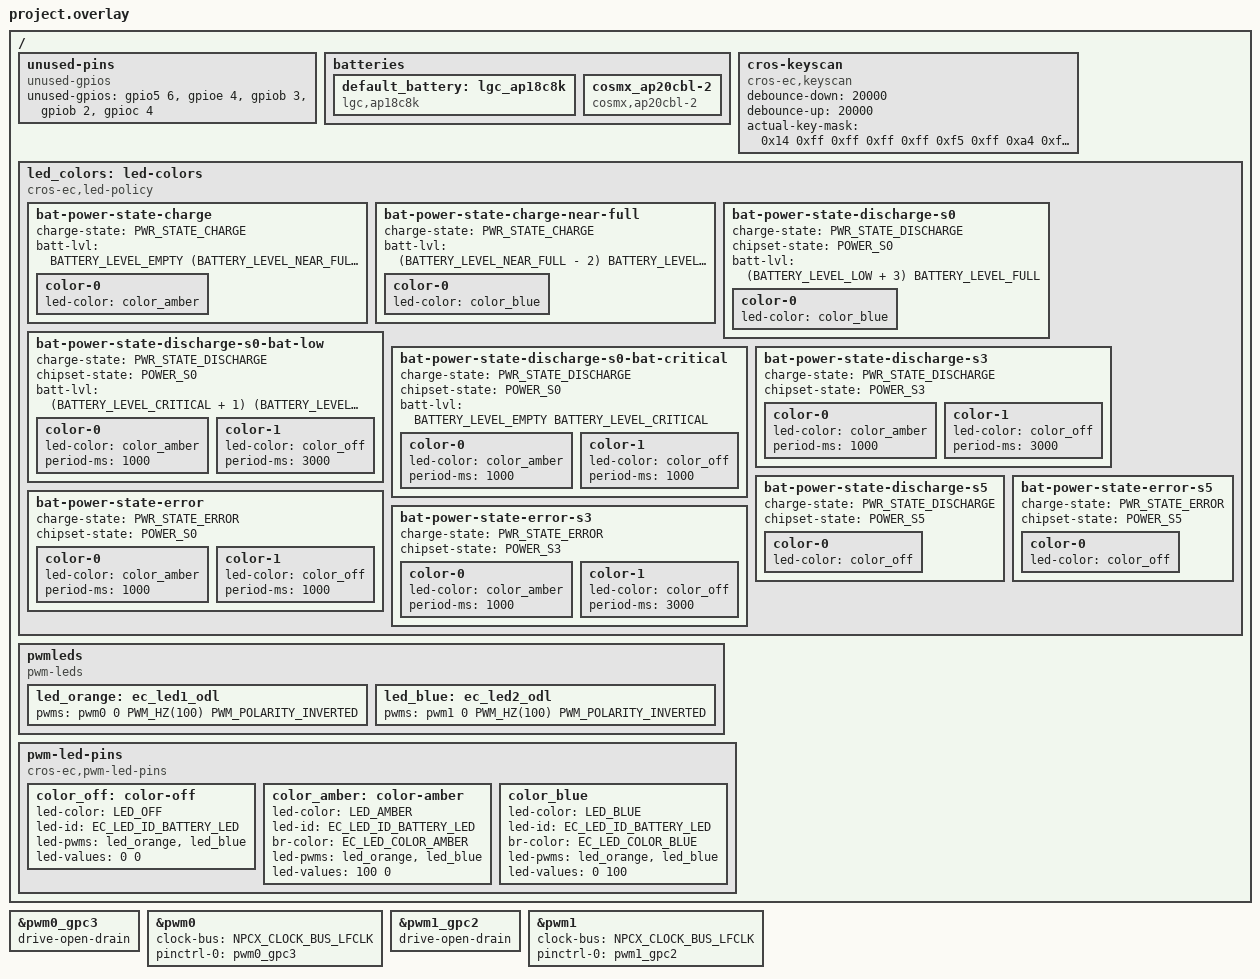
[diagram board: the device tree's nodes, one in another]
/* Copyright 2022 The ChromiumOS Authors
 * Use of this source code is governed by a BSD-style license that can be
 * found in the LICENSE file.
 */

/* Corsola program common DTS includes */

#include "../common.dtsi"
#include "../power_signal.dtsi"
#include "../usba.dtsi"
#include "../npcx_adc.dtsi"
#include "../npcx_gpio.dtsi"
#include "../npcx_host_interface.dtsi"
#include "../npcx_i2c.dtsi"
#include "../npcx_interrupts.dtsi"
#include "../npcx_keyboard.dtsi"
#include "../npcx_usbc.dtsi"
#include "../npcx_default_gpio_pinctrl.dtsi"
#include <dt-bindings/battery.h>

/* Projrect level DTS shared with tests */
#include "./interrupts.dtsi"

/* board override */
/delete-node/ &base_imu_int_l;
/delete-node/ &{/named-gpios/ec_pen_chg_dis_odl};
/delete-node/ &{/named-gpios/lid_accel_int_l};
/delete-node/ &gpio_tablet_mode_l;

/ {
	unused-pins {
		compatible = "unused-gpios";

		unused-gpios =
			/* base_imu_int_l */
			<&gpio5 6 0>,
			/* ec_pen_chg_dis_odl */
			<&gpioe 4 0>,
			/* lid_accel_int_l */
			<&gpiob 3 0>,
			/* gpio_tablet_mode_l */
			<&gpiob 2 0>,
			/* LED3 */
			<&gpioc 4 0>;
	};

	batteries {
		default_battery: lgc_ap18c8k {
			compatible = "lgc,ap18c8k", "battery-smart";
		};
		cosmx_ap20cbl-2 {
			compatible = "cosmx,ap20cbl-2", "battery-smart";
		};
	};

	cros-keyscan {
		compatible = "cros-ec,keyscan";

		debounce-down = <20000>;
		debounce-up = <20000>;

		actual-key-mask = <
			0x14	/* C0 */
			0xff	/* C1 */
			0xff	/* C2 */
			0xff	/* C3 */
			0xff	/* C4 */
			0xf5	/* C5 */
			0xff	/* C6 */
			0xa4	/* C7 */
			0xff	/* C8 */
			0xf6	/* C9 */
			0x55	/* C10 */
			0xfa	/* C11 */
			0xca	/* C12 */
		>;
	};

	led_colors: led-colors {
		compatible = "cros-ec,led-policy";

		/* Voltorb LED bat charge */
		bat-power-state-charge {
			charge-state = "PWR_STATE_CHARGE";
			/* Battery percent range (>= Empty, <= 94%) */
			batt-lvl = <BATTERY_LEVEL_EMPTY
					(BATTERY_LEVEL_NEAR_FULL - 3)>;
			color-0 {
				led-color = <&color_amber>;
			};
		};

		bat-power-state-charge-near-full {
			charge-state = "PWR_STATE_CHARGE";
			/* Battery percent range (>= 95%, <= Full) */
			batt-lvl = <(BATTERY_LEVEL_NEAR_FULL - 2)
					BATTERY_LEVEL_FULL>;
			color-0 {
				led-color = <&color_blue>;
			};
		};

		/* Voltorb LED bat discharge */
		bat-power-state-discharge-s0 {
			charge-state = "PWR_STATE_DISCHARGE";
			chipset-state = "POWER_S0";
			/* Battery percent range (>= 13%, <= Full) */
			batt-lvl = <(BATTERY_LEVEL_LOW + 3) BATTERY_LEVEL_FULL>;

			color-0 {
				led-color = <&color_blue>;
			};
		};


		bat-power-state-discharge-s0-bat-low {
			charge-state = "PWR_STATE_DISCHARGE";
			chipset-state = "POWER_S0";
			/* Battery percent range (>= 6%, <= 12%) */
			batt-lvl = <(BATTERY_LEVEL_CRITICAL + 1)
					(BATTERY_LEVEL_LOW + 2)>;

			color-0 {
				led-color = <&color_amber>;
				period-ms = <1000>;
			};

			color-1 {
				led-color = <&color_off>;
				period-ms = <3000>;
			};
		};

		bat-power-state-discharge-s0-bat-critical {
			charge-state = "PWR_STATE_DISCHARGE";
			chipset-state = "POWER_S0";
			/* Battery percent range (>= Empty, <= 5%) */
			batt-lvl = <BATTERY_LEVEL_EMPTY BATTERY_LEVEL_CRITICAL>;

			color-0 {
				led-color = <&color_amber>;
				period-ms = <1000>;
			};

			color-1 {
				led-color = <&color_off>;
				period-ms = <1000>;
			};
		};

		bat-power-state-discharge-s3 {
			charge-state = "PWR_STATE_DISCHARGE";
			chipset-state = "POWER_S3";

			color-0 {
				led-color = <&color_amber>;
				period-ms = <1000>;
			};

			color-1 {
				led-color = <&color_off>;
				period-ms = <3000>;
			};
		};

		bat-power-state-discharge-s5 {
			charge-state = "PWR_STATE_DISCHARGE";
			chipset-state = "POWER_S5";
			color-0 {
				led-color = <&color_off>;
			};
		};

		/* Voltorb LED bat error */
		bat-power-state-error {
			charge-state = "PWR_STATE_ERROR";
			chipset-state = "POWER_S0";

			color-0 {
				led-color = <&color_amber>;
				period-ms = <1000>;
			};

			color-1 {
				led-color = <&color_off>;
				period-ms = <1000>;
			};
		};

		bat-power-state-error-s3 {
			charge-state = "PWR_STATE_ERROR";
			chipset-state = "POWER_S3";

			color-0 {
				led-color = <&color_amber>;
				period-ms = <1000>;
			};

			color-1 {
				led-color = <&color_off>;
				period-ms = <3000>;
			};
		};

		bat-power-state-error-s5 {
			charge-state = "PWR_STATE_ERROR";
			chipset-state = "POWER_S5";

			color-0 {
				led-color = <&color_off>;
			};
		};
	};

	pwmleds {
		compatible = "pwm-leds";

		led_orange: ec_led1_odl {
			pwms = <&pwm0 0 PWM_HZ(100) PWM_POLARITY_INVERTED>;
		};

		led_blue: ec_led2_odl {
			pwms = <&pwm1 0 PWM_HZ(100) PWM_POLARITY_INVERTED>;
		};
	};

	pwm-led-pins {
		compatible = "cros-ec,pwm-led-pins";

		color_off: color-off {
			led-color = "LED_OFF";
			led-id = "EC_LED_ID_BATTERY_LED";
			led-pwms = <&led_orange &led_blue>;
			led-values = <0 0>;
		};

		color_amber: color-amber {
			led-color = "LED_AMBER";
			led-id = "EC_LED_ID_BATTERY_LED";
			br-color = "EC_LED_COLOR_AMBER";
			led-pwms = <&led_orange &led_blue>;
			led-values = <100 0>;
		};

		color_blue: color_blue {
			led-color = "LED_BLUE";
			led-id = "EC_LED_ID_BATTERY_LED";
			br-color = "EC_LED_COLOR_BLUE";
			led-pwms = <&led_orange &led_blue>;
			led-values = <0 100>;
		};
	};
};

/* Orange LED */
&pwm0_gpc3 {
	drive-open-drain;
};

&pwm0 {
	status = "okay";
	clock-bus = "NPCX_CLOCK_BUS_LFCLK";
	pinctrl-0 = <&pwm0_gpc3>;
	pinctrl-names = "default";
};

/* Blue LED */
&pwm1_gpc2 {
	drive-open-drain;
};

&pwm1 {
	status = "okay";
	clock-bus = "NPCX_CLOCK_BUS_LFCLK";
	pinctrl-0 = <&pwm1_gpc2>;
	pinctrl-names = "default";
};
